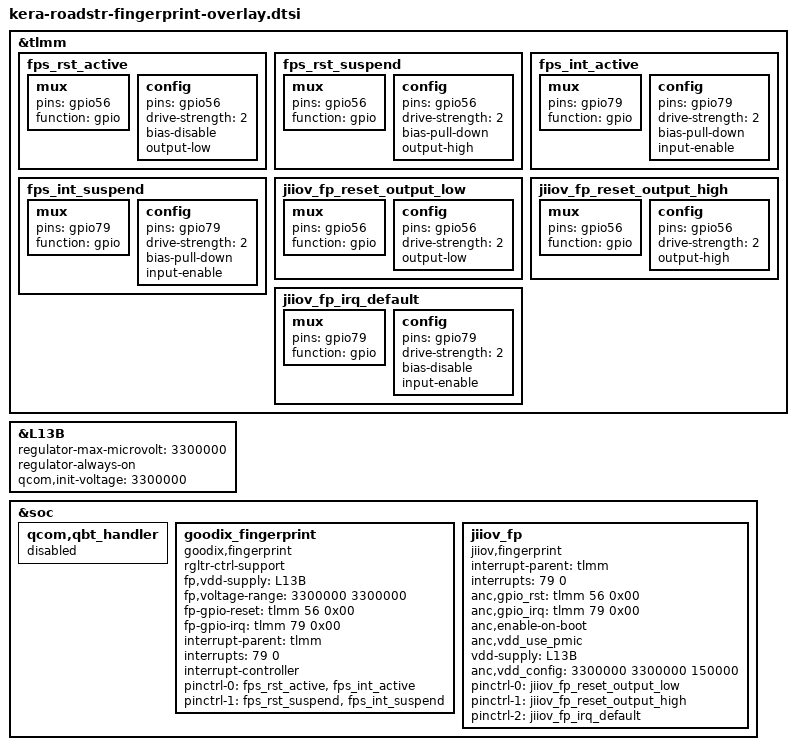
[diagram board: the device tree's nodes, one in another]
/* Copyright (c) 2021, The Linux Foundation. All rights reserved.
 *
 * This program is free software; you can redistribute it and/or modify
 * it under the terms of the GNU General Public License version 2 and
 * only version 2 as published by the Free Software Foundation.
 *
 * This program is distributed in the hope that it will be useful,
 * but WITHOUT ANY WARRANTY; without even the implied warranty of
 * MERCHANTABILITY or FITNESS FOR A PARTICULAR PURPOSE.  See the
 * GNU General Public License for more details.
 */

#include <dt-bindings/regulator/qcom,rpmh-regulator-levels.h>

&tlmm {

	fps_rst_active: fps_rst_active {
			/* RESET */
			mux {
				pins = "gpio56";
				function = "gpio";
			};
			config {
				pins = "gpio56";
				drive-strength = <2>; /* 2 MA */
				bias-disable;
				output-low;
			};
	};

	fps_rst_suspend: fps_rst_suspend {
		/* sleep state */
		mux {
			pins = "gpio56";
			function = "gpio";
		};

		config {
			pins = "gpio56";
			drive-strength = <2>; /* 2 MA */
			bias-pull-down; /* pull down */
			output-high;
		};
	};

	fps_int_active: fps_int_active {
		/* active state */
		mux {
			pins = "gpio79";
			function = "gpio";
		};

		config {
			pins = "gpio79";
			drive-strength = <2>; /* 2 MA */
			bias-pull-down; /* pull down */
			input-enable;
		};
	};

	fps_int_suspend: fps_int_suspend {
		/* sleep state */
		mux {
			pins = "gpio79";
			function = "gpio";
		};

		config {
			pins = "gpio79";
			drive-strength = <2>; /* 2 MA */
			bias-pull-down; /* pull down */
			input-enable;
		};
	};
	jiiov_fp_reset_output_low: jiiov_fp_reset_output_low {
		/* active state */
		mux {
		        pins = "gpio56";
		        function = "gpio";
		};

		config {
		        pins = "gpio56";
		        drive-strength = <2>; /* 2 MA */
		        output-low;
		};
	};

	jiiov_fp_reset_output_high: jiiov_fp_reset_output_high {
		/* active state */
		mux {
		        pins = "gpio56";
		        function = "gpio";
		};

		config {
		        pins = "gpio56";
		        drive-strength = <2>; /* 2 MA */
		        output-high;
		};
	};

	jiiov_fp_irq_default: jiiov_fp_irq_default {
		mux {
		        pins = "gpio79";
		        function = "gpio";
		};

		config {
		        pins = "gpio79";
		        drive-strength = <2>; /* 2 MA */
		        bias-disable;
		        input-enable;
		};
	};
};

&L13B {
		regulator-max-microvolt = <3300000>;
		regulator-always-on;
		qcom,init-voltage = <3300000>;
		status = "ok";
	};

&soc {
	qcom,qbt_handler {
		status = "disabled";
	};
	goodix_fingerprint {
		compatible = "goodix,fingerprint";
		status = "ok";
		rgltr-ctrl-support;
		fp,vdd-supply = <&L13B>;
		fp,voltage-range = <3300000 3300000>;
		fp-gpio-reset = <&tlmm 56 0x00>;
		fp-gpio-irq = <&tlmm 79 0x00>;
		interrupt-parent = <&tlmm>;
		interrupts = <79 0>;
		interrupt-controller;
		pinctrl-names = "default", "suspend";
		pinctrl-0 = <&fps_rst_active &fps_int_active>;
		pinctrl-1 = <&fps_rst_suspend &fps_int_suspend>;
	};

	jiiov_fp {
		status = "ok";
		compatible = "jiiov,fingerprint";
		interrupt-parent = <&tlmm>;
		interrupts = <79 0>;
		anc,gpio_rst = <&tlmm 56 0x00>;
		anc,gpio_irq = <&tlmm 79 0x00>;
		anc,enable-on-boot;
		//anc,vdd_use_gpio;
		//anc,gpio_pwr = <&tlmm 132 0x0>;
		anc,vdd_use_pmic;
		vdd-supply = <&L13B>;
		anc,vdd_config = <3300000 3300000 150000>;
		pinctrl-names = "anc_reset_low",
		"anc_reset_high",
		"anc_irq_default";

		pinctrl-0 = <&jiiov_fp_reset_output_low>;
		pinctrl-1 = <&jiiov_fp_reset_output_high>;
		pinctrl-2 = <&jiiov_fp_irq_default>;
	};
};
